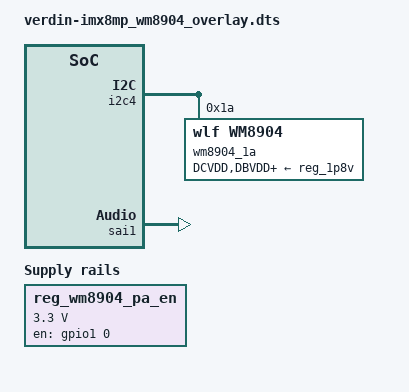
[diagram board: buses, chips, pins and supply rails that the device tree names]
/dts-v1/;
/plugin/;

#include "imx8mp-pinfunc.h"
#include <dt-bindings/gpio/gpio.h>
#include <dt-bindings/clock/imx8mp-clock.h>

&{/} {
    /* Power Amplifier Enable Regulator */
    reg_wm8904_pa_en: regulator-wm8904-pa-en {
        compatible = "regulator-fixed";
        regulator-name = "reg_wm8904_pa_en";
        regulator-min-microvolt = <3300000>;
        regulator-max-microvolt = <3300000>;
        /* SODIMM 206 -> GPIO1_IO00 */
        gpio = <&gpio1 0 GPIO_ACTIVE_HIGH>;
        enable-active-high;
        regulator-always-on;
    };

    /* Simple Audio Card setup */
    sound_wm8904: sound-wm8904 {
        compatible = "simple-audio-card";
        simple-audio-card,name = "verdin-wm8904";
        simple-audio-card,format = "i2s";
        simple-audio-card,bitclock-master = <&codec_dai>;
        simple-audio-card,frame-master = <&codec_dai>;
        simple-audio-card,mclk-fs = <256>;

        simple-audio-card,widgets =
            "Microphone", "Microphone Jack",
            "Headphone", "Headphone Jack",
            "Line", "Line In Jack";
        simple-audio-card,routing =
            "Headphone Jack", "HPOUTL",
            "Headphone Jack", "HPOUTR",
            "IN2L", "Line In Jack",
            "IN2R", "Line In Jack",
            "Microphone Jack", "MICBIAS",
            "IN1L", "Microphone Jack";

        simple-audio-card,cpu {
            sound-dai = <&sai1>;
        };

        codec_dai: simple-audio-card,codec {
            sound-dai = <&wm8904_1a>;
            clocks = <&audio_blk_ctrl IMX8MP_CLK_AUDIOMIX_SAI1_MCLK1>;
        };
    };
};

&i2c4 {
    #address-cells = <1>;
    #size-cells = <0>;
    status = "okay";

    wm8904_1a: wm8904@1a {
        compatible = "wlf,wm8904";
        reg = <0x1a>;
        pinctrl-names = "default";
        pinctrl-0 = <&pinctrl_sai1>;
        #sound-dai-cells = <0>;
        clocks = <&audio_blk_ctrl IMX8MP_CLK_AUDIOMIX_SAI1_MCLK1>;
        clock-names = "mclk";
        /* Use standard carrier board supplies */
        DCVDD-supply = <&reg_1p8v>;
        DBVDD-supply = <&reg_1p8v>;
        AVDD-supply = <&reg_1p8v>;
        CPVDD-supply = <&reg_1p8v>;
        MICVDD-supply = <&reg_1p8v>;
        status = "okay";
    };
};

&sai1 {
    assigned-clocks = <&clk IMX8MP_CLK_SAI1>;
    assigned-clock-parents = <&clk IMX8MP_AUDIO_PLL1_OUT>;
    assigned-clock-rates = <24576000>;
    fsl,sai-mclk-direction-output;
    status = "okay";
};

/* 
 * Ensure the pins are available for SAI1 and I2C4 
 * and not blocked by default pin hogs.
 */
&iomuxc {
    /delete-property/ pinctrl-0;

    pinctrl-0 = <&pinctrl_gpio2>,
                <&pinctrl_gpio3>, <&pinctrl_gpio4>,
                <&pinctrl_gpio7>, <&pinctrl_gpio8>,
                <&pinctrl_gpio_hog2>, <&pinctrl_gpio_hog4>,
                <&pinctrl_hdmi_hog>;
};
